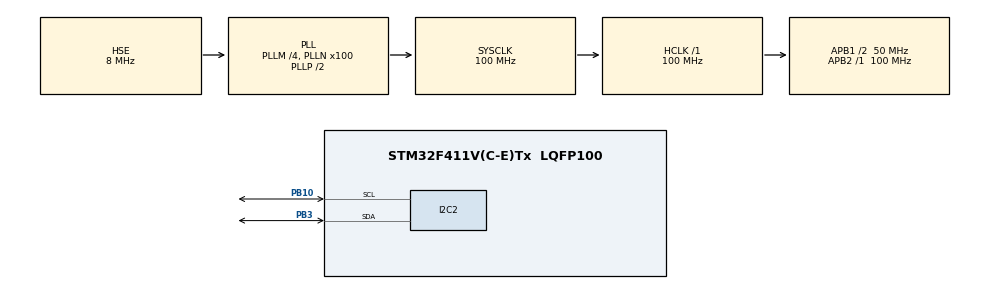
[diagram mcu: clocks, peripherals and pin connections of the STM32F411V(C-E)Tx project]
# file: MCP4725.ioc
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I2C2.I2C_Mode=I2C_Fast
Mcu.Family=STM32F4
Mcu.Name=STM32F411V(C-E)Tx
Mcu.Package=LQFP100
NVIC.PriorityGroup=NVIC_PRIORITYGROUP_4
NVIC.TIM1_UP_TIM10_IRQn=true\:0\:0\:false\:false\:true\:true\:true
PA13.Mode=Serial_Wire
PA13.Signal=SYS_JTMS-SWDIO
PA14.Mode=Serial_Wire
PA14.Signal=SYS_JTCK-SWCLK
PB10.Mode=I2C
PB10.Signal=I2C2_SCL
PB3.Mode=I2C
PB3.Signal=I2C2_SDA
PH0\ -\ OSC_IN.Mode=HSE-External-Oscillator
PH0\ -\ OSC_IN.Signal=RCC_OSC_IN
PH1\ -\ OSC_OUT.Mode=HSE-External-Oscillator
PH1\ -\ OSC_OUT.Signal=RCC_OSC_OUT
ProjectManager.HeapSize=0x200
ProjectManager.StackSize=0x400
ProjectManager.TargetToolchain=MDK-ARM V5.27
RCC.48MHZClocksFreq_Value=50000000
RCC.AHBFreq_Value=100000000
RCC.APB1CLKDivider=RCC_HCLK_DIV2
RCC.APB1Freq_Value=50000000
RCC.APB1TimFreq_Value=100000000
RCC.APB2Freq_Value=100000000
RCC.APB2TimFreq_Value=100000000
RCC.CortexFreq_Value=100000000
RCC.HCLKFreq_Value=100000000
RCC.HSE_VALUE=8000000
RCC.HSI_VALUE=16000000
RCC.LSE_VALUE=32768
RCC.PLLM=4
RCC.PLLN=100
RCC.PLLSourceVirtual=RCC_PLLSOURCE_HSE
RCC.SYSCLKFreq_VALUE=100000000
RCC.SYSCLKSource=RCC_SYSCLKSOURCE_PLLCLK
RCC.VCOOutputFreq_Value=200000000
TIM1.Period=200-1
TIM1.Prescaler=100-1
VP_TIM1_VS_ClockSourceINT.Mode=Internal
board=custom

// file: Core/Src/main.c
/* USER CODE BEGIN Header */
/**
  ******************************************************************************
  * @file           : main.c
  * @brief          : Main program body
  ******************************************************************************
  * @attention
  *
  * <h2><center>&copy; Copyright (c) 2021 STMicroelectronics.
  * All rights reserved.</center></h2>
  *
  * This software component is licensed by ST under BSD 3-Clause license,
  * the "License"; You may not use this file except in compliance with the
  * License. You may obtain a copy of the License at:
  *                        opensource.org/licenses/BSD-3-Clause
  *
  ******************************************************************************
  */
/* USER CODE END Header */
#include "main.h"
#include "i2c.h"
#include "tim.h"
#include "gpio.h"

/* USER CODE BEGIN Includes */
#include "MCP4725.h"
/* USER CODE END Includes */

void SystemClock_Config(void);
/* USER CODE BEGIN PFP */
uint8_t setValue(uint16_t value);
/* USER CODE END PFP */

/* USER CODE BEGIN 0 */

	// First, create an MCP4725 object:
	MCP4725 myMCP4725;

	uint32_t micro_seconds = 0;

/* USER CODE END 0 */

int main(void)
{

  /* MCU Configuration--------------------------------------------------------*/

  /* Reset of all peripherals, Initializes the Flash interface and the Systick. */
  HAL_Init();

  /* Configure the system clock */
  SystemClock_Config();

  /* Initialize all configured peripherals */
  MX_GPIO_Init();
  MX_I2C2_Init();
  MX_TIM1_Init();
  /* USER CODE BEGIN 2 */

		// Second, initilaize the MCP4725 object:
		myMCP4725 = MCP4725_init(&hi2c2, MCP4725A0_ADDR_A00, 3.30);

		// Check the connection:
		if(MCP4725_isConnected(&myMCP4725)){

			/* Print that the DAC is coonected */

		}
		else{

			/* Print that the DAC is NOT coonected */

		}

		// Starting the timer:
		HAL_TIM_Base_Start_IT(&htim1);

  /* USER CODE END 2 */

  /* Infinite loop */
  while (1)
  {

  }
}

void SystemClock_Config(void)
{
  RCC_OscInitTypeDef RCC_OscInitStruct = {0};
  RCC_ClkInitTypeDef RCC_ClkInitStruct = {0};

  /** Configure the main internal regulator output voltage
  */
  __HAL_RCC_PWR_CLK_ENABLE();
  __HAL_PWR_VOLTAGESCALING_CONFIG(PWR_REGULATOR_VOLTAGE_SCALE1);
  /** Initializes the RCC Oscillators according to the specified parameters
  * in the RCC_OscInitTypeDef structure.
  */
  RCC_OscInitStruct.OscillatorType = RCC_OSCILLATORTYPE_HSE;
  RCC_OscInitStruct.HSEState = RCC_HSE_ON;
  RCC_OscInitStruct.PLL.PLLState = RCC_PLL_ON;
  RCC_OscInitStruct.PLL.PLLSource = RCC_PLLSOURCE_HSE;
  RCC_OscInitStruct.PLL.PLLM = 4;
  RCC_OscInitStruct.PLL.PLLN = 100;
  RCC_OscInitStruct.PLL.PLLP = RCC_PLLP_DIV2;
  RCC_OscInitStruct.PLL.PLLQ = 4;
  if (HAL_RCC_OscConfig(&RCC_OscInitStruct) != HAL_OK)
  {
    Error_Handler();
  }
  /** Initializes the CPU, AHB and APB buses clocks
  */
  RCC_ClkInitStruct.ClockType = RCC_CLOCKTYPE_HCLK|RCC_CLOCKTYPE_SYSCLK
                              |RCC_CLOCKTYPE_PCLK1|RCC_CLOCKTYPE_PCLK2;
  RCC_ClkInitStruct.SYSCLKSource = RCC_SYSCLKSOURCE_PLLCLK;
  RCC_ClkInitStruct.AHBCLKDivider = RCC_SYSCLK_DIV1;
  RCC_ClkInitStruct.APB1CLKDivider = RCC_HCLK_DIV2;
  RCC_ClkInitStruct.APB2CLKDivider = RCC_HCLK_DIV1;

  if (HAL_RCC_ClockConfig(&RCC_ClkInitStruct, FLASH_LATENCY_3) != HAL_OK)
  {
    Error_Handler();
  }
}

/* USER CODE BEGIN 4 */
void HAL_TIM_PeriodElapsedCallback(TIM_HandleTypeDef *htim)
{
	// Create a 100Hz sine wave:
	setValue((uint16_t)( sinf( 2 * 3.141592 * 100 * (micro_seconds++) / 10000.0 ) * 2047 + 2048));
}

uint8_t setValue(uint16_t value){
	return MCP4725_setValue(&myMCP4725, value, MCP4725_FAST_MODE, MCP4725_POWER_DOWN_OFF);
}
/* USER CODE END 4 */

void Error_Handler(void)
{
  __disable_irq();
  while (1)
  {
  }
}

/************************ (C) COPYRIGHT STMicroelectronics *****END OF FILE****/
